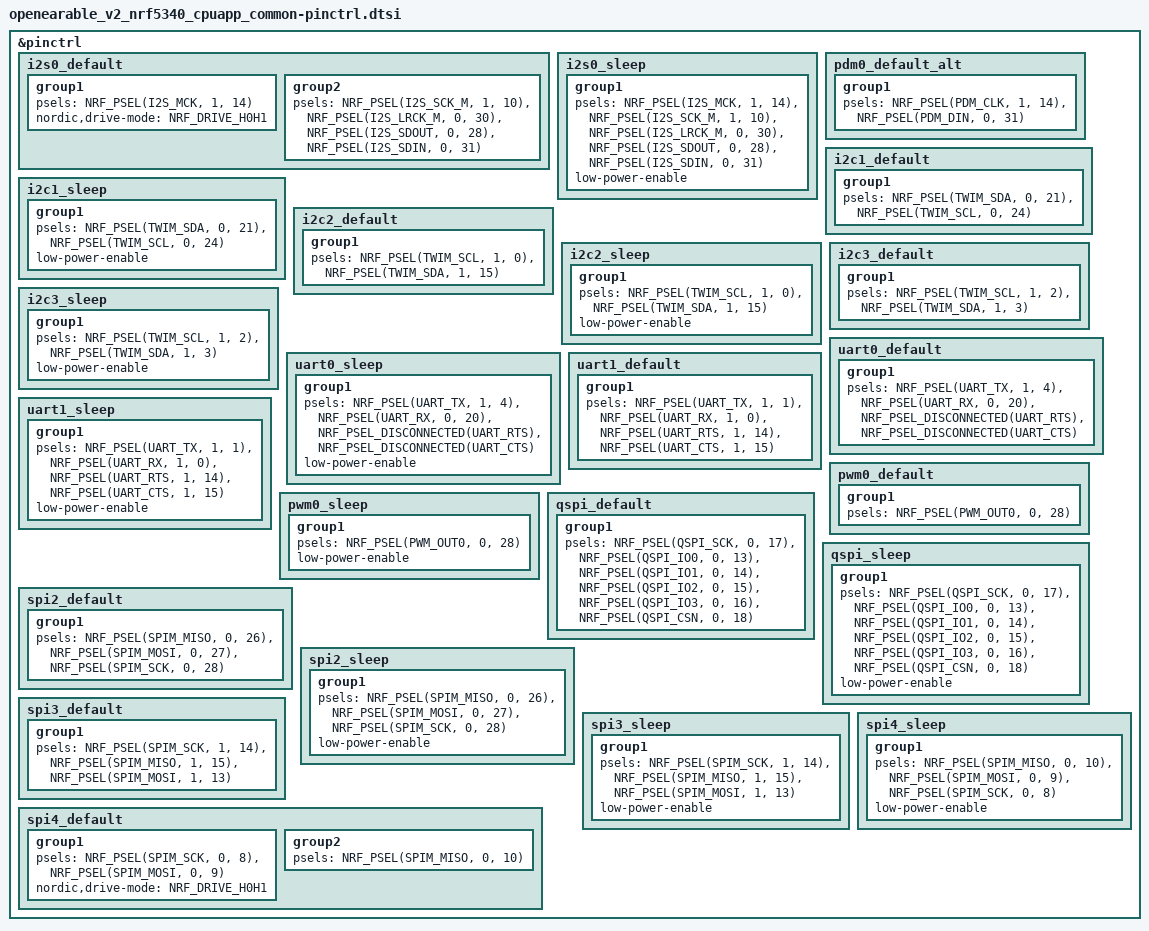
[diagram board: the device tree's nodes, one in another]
/*
 * Copyright (c) 2023 Raytac Corporation
 *
 * SPDX-License-Identifier: Apache-2.0
 */

 &pinctrl {
	i2s0_default: i2s0_default {
		group1 {
			psels = <NRF_PSEL(I2S_MCK, 1, 14)>;
			nordic,drive-mode = <NRF_DRIVE_H0H1>;
		};
		group2 {
			psels = <NRF_PSEL(I2S_SCK_M, 1, 10)>,
			<NRF_PSEL(I2S_LRCK_M, 0, 30)>,
			<NRF_PSEL(I2S_SDOUT, 0, 28)>,
			<NRF_PSEL(I2S_SDIN, 0, 31)>;
		};
	};

	i2s0_sleep: i2s0_sleep {
		group1 {
			psels = <NRF_PSEL(I2S_MCK, 1, 14)>,
				<NRF_PSEL(I2S_SCK_M, 1, 10)>,
				<NRF_PSEL(I2S_LRCK_M, 0, 30)>,
				<NRF_PSEL(I2S_SDOUT, 0, 28)>,
				<NRF_PSEL(I2S_SDIN, 0, 31)>;
				// <NRF_PSEL(I2S_SDIN, 0, 15)>
				// <NRF_PSEL(I2S_MCK, 0, 12)>
			low-power-enable;
		};
	};

	pdm0_default_alt: pdm0_default_alt {
		group1 {
			psels = <NRF_PSEL(PDM_CLK, 1, 14)>,
				<NRF_PSEL(PDM_DIN, 0, 31)>;
		};
	};

	i2c1_default: i2c1_default {
		group1 {
			psels = <NRF_PSEL(TWIM_SDA, 0, 21)>,
				<NRF_PSEL(TWIM_SCL, 0, 24)>;
		};
	};

	i2c1_sleep: i2c1_sleep {
		group1 {
			psels = <NRF_PSEL(TWIM_SDA, 0, 21)>,
				<NRF_PSEL(TWIM_SCL, 0, 24)>;
			low-power-enable;
		};
	};

	i2c2_default: i2c2_default {
		group1 {
			psels = <NRF_PSEL(TWIM_SCL, 1, 0)>,
				<NRF_PSEL(TWIM_SDA, 1, 15)>;
		};
	};

	i2c2_sleep: i2c2_sleep {
		group1 {
			psels = <NRF_PSEL(TWIM_SCL, 1, 0)>,
				<NRF_PSEL(TWIM_SDA, 1, 15)>;
			low-power-enable;
		};
	};

	i2c3_default: i2c3_default {
		group1 {
			psels = <NRF_PSEL(TWIM_SCL, 1, 2)>,
				<NRF_PSEL(TWIM_SDA, 1, 3)>;
		};
	};

	i2c3_sleep: i2c3_sleep {
		group1 {
			psels = <NRF_PSEL(TWIM_SCL, 1, 2)>,
				<NRF_PSEL(TWIM_SDA, 1, 3)>;
			low-power-enable;
		};
	};

	uart0_default: uart0_default {
		group1 {
			psels = <NRF_PSEL(UART_TX, 1, 4)>,
				<NRF_PSEL(UART_RX, 0, 20)>,
				<NRF_PSEL_DISCONNECTED(UART_RTS)>,
				<NRF_PSEL_DISCONNECTED(UART_CTS)>;
		};
	};

	uart0_sleep: uart0_sleep {
		group1 {
			psels = <NRF_PSEL(UART_TX, 1, 4)>,
				<NRF_PSEL(UART_RX, 0, 20)>,
				<NRF_PSEL_DISCONNECTED(UART_RTS)>,
				<NRF_PSEL_DISCONNECTED(UART_CTS)>;
			low-power-enable;
		};
	};

	uart1_default: uart1_default {
		group1 {
			psels = <NRF_PSEL(UART_TX, 1, 1)>,
				<NRF_PSEL(UART_RX, 1, 0)>,
				<NRF_PSEL(UART_RTS, 1, 14)>,
				<NRF_PSEL(UART_CTS, 1, 15)>;
		};
	};

	uart1_sleep: uart1_sleep {
		group1 {
			psels = <NRF_PSEL(UART_TX, 1, 1)>,
				<NRF_PSEL(UART_RX, 1, 0)>,
				<NRF_PSEL(UART_RTS, 1, 14)>,
				<NRF_PSEL(UART_CTS, 1, 15)>;
			low-power-enable;
		};
	};

	pwm0_default: pwm0_default {
		group1 {
			psels = <NRF_PSEL(PWM_OUT0, 0, 28)>;
		};
	};

	pwm0_sleep: pwm0_sleep {
		group1 {
			psels = <NRF_PSEL(PWM_OUT0, 0, 28)>;
			low-power-enable;
		};
	};

	qspi_default: qspi_default {
		group1 {
			psels = <NRF_PSEL(QSPI_SCK, 0, 17)>,
				<NRF_PSEL(QSPI_IO0, 0, 13)>,
				<NRF_PSEL(QSPI_IO1, 0, 14)>,
				<NRF_PSEL(QSPI_IO2, 0, 15)>,
				<NRF_PSEL(QSPI_IO3, 0, 16)>,
				<NRF_PSEL(QSPI_CSN, 0, 18)>;
		};
	};

	qspi_sleep: qspi_sleep {
		group1 {
			psels = <NRF_PSEL(QSPI_SCK, 0, 17)>,
				<NRF_PSEL(QSPI_IO0, 0, 13)>,
				<NRF_PSEL(QSPI_IO1, 0, 14)>,
				<NRF_PSEL(QSPI_IO2, 0, 15)>,
				<NRF_PSEL(QSPI_IO3, 0, 16)>,
				<NRF_PSEL(QSPI_CSN, 0, 18)>;
			low-power-enable;
		};
	};

	spi2_default: spi2_default {
		group1 {
			psels = <NRF_PSEL(SPIM_MISO, 0, 26)>,
				<NRF_PSEL(SPIM_MOSI, 0, 27)>,
				<NRF_PSEL(SPIM_SCK, 0, 28)>;
		};
	};

	spi2_sleep: spi2_sleep {
		group1 {
			psels = <NRF_PSEL(SPIM_MISO, 0, 26)>,
				<NRF_PSEL(SPIM_MOSI, 0, 27)>,
				<NRF_PSEL(SPIM_SCK, 0, 28)>;
			low-power-enable;
		};
	};

	spi3_default: spi3_default {
		group1 {
			psels = <NRF_PSEL(SPIM_SCK, 1, 14)>,
				<NRF_PSEL(SPIM_MISO, 1, 15)>,
				<NRF_PSEL(SPIM_MOSI, 1, 13)>;
		};
	};

	spi3_sleep: spi3_sleep {
		group1 {
			psels = <NRF_PSEL(SPIM_SCK, 1, 14)>,
				<NRF_PSEL(SPIM_MISO, 1, 15)>,
				<NRF_PSEL(SPIM_MOSI, 1, 13)>;
			low-power-enable;
		};
	};

	spi4_default: spi4_default {
		group1 {
			psels = <NRF_PSEL(SPIM_SCK, 0, 8)>,
				<NRF_PSEL(SPIM_MOSI, 0, 9)>;
			/* Workaround for issue with PCA10121 v0.7.0
			 * related to SD-card
			 */
			nordic,drive-mode = <NRF_DRIVE_H0H1>;
		};
		group2 {
			psels = <NRF_PSEL(SPIM_MISO, 0, 10)>;
		};
	};

	spi4_sleep: spi4_sleep {
		group1 {
			psels = <NRF_PSEL(SPIM_MISO, 0, 10)>,
				<NRF_PSEL(SPIM_MOSI, 0, 9)>,
				<NRF_PSEL(SPIM_SCK, 0, 8)>;
			low-power-enable;
		};
	};
};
